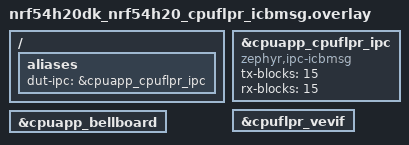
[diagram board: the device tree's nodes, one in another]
/*
 * Copyright (c) 2026 Nordic Semiconductor ASA
 *
 * SPDX-License-Identifier: Apache-2.0
 */

&cpuapp_cpuflpr_ipc {
	status = "okay";
	compatible = "zephyr,ipc-icbmsg";
	tx-blocks = <15>;
	rx-blocks = <15>;
};

/ {
	aliases {
		dut-ipc = &cpuapp_cpuflpr_ipc;
	};
};

&cpuflpr_vevif {
	status = "okay";
};

&cpuapp_bellboard {
	status = "okay";
};
